AUTOSAR XML (schema 314)
package /ComponentType
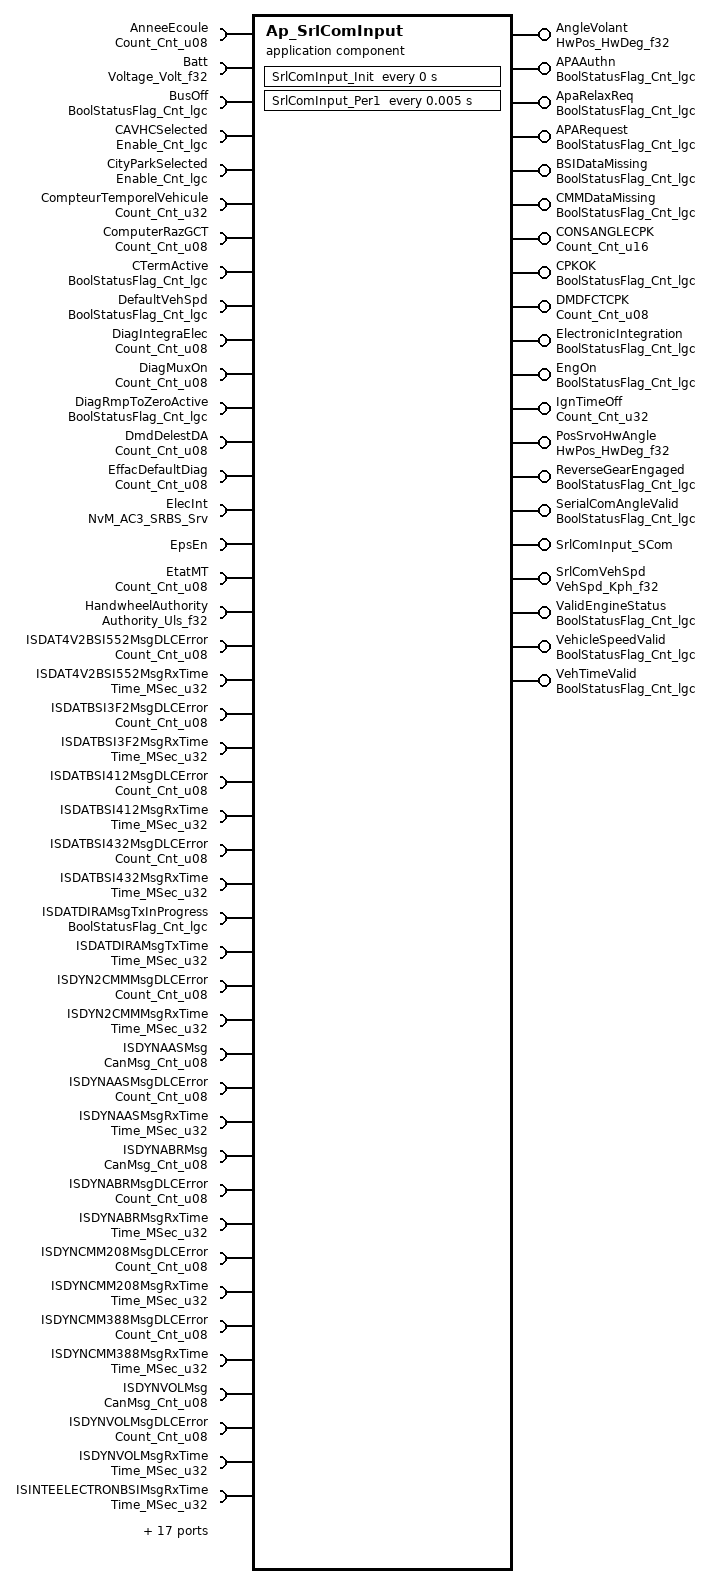
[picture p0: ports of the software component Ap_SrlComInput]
  application software component type Ap_SrlComInput
    20 x provide port:
      AngleVolant: unqueued-sender-com-spec{data-element=HwDeg_f32, can-invalidate=false, init-value=D_ZERO_ULS_F32}, provided-interface=HwPos_HwDeg_f32
      APAAuthn: unqueued-sender-com-spec{data-element=Cnt_lgc, can-invalidate=false, init-value=D_FALSE_CNT_LGC}, provided-interface=BoolStatusFlag_Cnt_lgc
      ApaRelaxReq: unqueued-sender-com-spec{data-element=Cnt_lgc, can-invalidate=false, init-value=D_FALSE_CNT_LGC}, provided-interface=BoolStatusFlag_Cnt_lgc
      APARequest: unqueued-sender-com-spec{data-element=Cnt_lgc, can-invalidate=false, init-value=D_FALSE_CNT_LGC}, provided-interface=BoolStatusFlag_Cnt_lgc
      BSIDataMissing: unqueued-sender-com-spec{data-element=Cnt_lgc, can-invalidate=false, init-value=D_TRUE_CNT_LGC}, provided-interface=BoolStatusFlag_Cnt_lgc
      CMMDataMissing: unqueued-sender-com-spec{data-element=Cnt_lgc, can-invalidate=false, init-value=D_TRUE_CNT_LGC}, provided-interface=BoolStatusFlag_Cnt_lgc
      CONSANGLECPK: unqueued-sender-com-spec{data-element=Cnt_u16, can-invalidate=false, init-value=D_ZERO_CNT_U16}, provided-interface=Count_Cnt_u16
      CPKOK: unqueued-sender-com-spec{data-element=Cnt_lgc, can-invalidate=false, init-value=D_FALSE_CNT_LGC}, provided-interface=BoolStatusFlag_Cnt_lgc
      DMDFCTCPK: unqueued-sender-com-spec{data-element=Cnt_u08, can-invalidate=false, init-value=D_ZERO_CNT_U8}, provided-interface=Count_Cnt_u08
      ElectronicIntegration: unqueued-sender-com-spec{data-element=Cnt_lgc, can-invalidate=false, init-value=D_FALSE_CNT_LGC}, provided-interface=BoolStatusFlag_Cnt_lgc
      EngOn: unqueued-sender-com-spec{data-element=Cnt_lgc, can-invalidate=false, init-value=D_FALSE_CNT_LGC}, provided-interface=BoolStatusFlag_Cnt_lgc
      IgnTimeOff: unqueued-sender-com-spec{data-element=Cnt_u32, can-invalidate=false, init-value=D_ZERO_CNT_U32}, provided-interface=Count_Cnt_u32
      PosSrvoHwAngle: unqueued-sender-com-spec{data-element=HwDeg_f32, can-invalidate=false, init-value=D_ZERO_ULS_F32}, provided-interface=HwPos_HwDeg_f32
      ReverseGearEngaged: unqueued-sender-com-spec{data-element=Cnt_lgc, can-invalidate=false, init-value=D_FALSE_CNT_LGC}, provided-interface=BoolStatusFlag_Cnt_lgc
      SerialComAngleValid: unqueued-sender-com-spec{data-element=Cnt_lgc, can-invalidate=false, init-value=D_FALSE_CNT_LGC}, provided-interface=BoolStatusFlag_Cnt_lgc
      SrlComInput_SCom: provided-interface=SrlComInput_SCom
        provided-com-specs:
          operation=GetNetworkDiagFltAcc, queue-length=1
          operation=ManualVehSpd, queue-length=1
          operation=ResetTimers, queue-length=1
          operation=VehSpdControl, queue-length=1
      SrlComVehSpd: unqueued-sender-com-spec{data-element=Kph_f32, can-invalidate=false, init-value=D_ZERO_ULS_F32}, provided-interface=VehSpd_Kph_f32
      ValidEngineStatus: unqueued-sender-com-spec{data-element=Cnt_lgc, can-invalidate=false, init-value=D_FALSE_CNT_LGC}, provided-interface=BoolStatusFlag_Cnt_lgc
      VehicleSpeedValid: unqueued-sender-com-spec{data-element=Cnt_lgc, can-invalidate=false, init-value=D_FALSE_CNT_LGC}, provided-interface=BoolStatusFlag_Cnt_lgc
      VehTimeValid: unqueued-sender-com-spec{data-element=Cnt_lgc, can-invalidate=false, init-value=D_FALSE_CNT_LGC}, provided-interface=BoolStatusFlag_Cnt_lgc
    61 x require port:
      AnneeEcoule: unqueued-receiver-com-spec{data-element=Cnt_u08, init-value=D_ZERO_CNT_U8}, required-interface=Count_Cnt_u08
      Batt: unqueued-receiver-com-spec{data-element=Volt_f32, init-value=D_ZERO_ULS_F32}, required-interface=Voltage_Volt_f32
      BusOff: unqueued-receiver-com-spec{data-element=Cnt_lgc, init-value=D_FALSE_CNT_LGC}, required-interface=BoolStatusFlag_Cnt_lgc
      CAVHCSelected: unqueued-receiver-com-spec{data-element=Cnt_lgc, init-value=D_FALSE_CNT_LGC}, required-interface=Enable_Cnt_lgc
      CityParkSelected: unqueued-receiver-com-spec{data-element=Cnt_lgc, init-value=D_FALSE_CNT_LGC}, required-interface=Enable_Cnt_lgc
      CompteurTemporelVehicule: unqueued-receiver-com-spec{data-element=Cnt_u32, init-value=D_ZERO_CNT_U32}, required-interface=Count_Cnt_u32
      ComputerRazGCT: unqueued-receiver-com-spec{data-element=Cnt_u08, init-value=D_ZERO_CNT_U8}, required-interface=Count_Cnt_u08
      CTermActive: unqueued-receiver-com-spec{data-element=Cnt_lgc, init-value=D_FALSE_CNT_LGC}, required-interface=BoolStatusFlag_Cnt_lgc
      DefaultVehSpd: unqueued-receiver-com-spec{data-element=Cnt_lgc, init-value=D_FALSE_CNT_LGC}, required-interface=BoolStatusFlag_Cnt_lgc
      DiagIntegraElec: unqueued-receiver-com-spec{data-element=Cnt_u08, init-value=D_ZERO_CNT_U8}, required-interface=Count_Cnt_u08
      DiagMuxOn: unqueued-receiver-com-spec{data-element=Cnt_u08, init-value=D_ZERO_CNT_U8}, required-interface=Count_Cnt_u08
      DiagRmpToZeroActive: unqueued-receiver-com-spec{data-element=Cnt_lgc, init-value=D_FALSE_CNT_LGC}, required-interface=BoolStatusFlag_Cnt_lgc
      DmdDelestDA: unqueued-receiver-com-spec{data-element=Cnt_u08, init-value=D_ZERO_CNT_U8}, required-interface=Count_Cnt_u08
      EffacDefaultDiag: unqueued-receiver-com-spec{data-element=Cnt_u08, init-value=D_ZERO_CNT_U8}, required-interface=Count_Cnt_u08
      ElecInt: required-com-specs=[EraseBlock, GetErrorStatus, InvalidateNvBlock, ReadBlock, SetRamBlockStatus, WriteBlock], required-interface=NvM_AC3_SRBS_Srv
      EpsEn: client-com-spec=OP_GET, required-interface=EpsEn
      EtatMT: unqueued-receiver-com-spec{data-element=Cnt_u08, init-value=D_ZERO_CNT_U8}, required-interface=Count_Cnt_u08
      HandwheelAuthority: unqueued-receiver-com-spec{data-element=Uls_f32, init-value=D_ZERO_ULS_F32}, required-interface=Authority_Uls_f32
      ISDAT4V2BSI552MsgDLCError: unqueued-receiver-com-spec{data-element=Cnt_u08, init-value=D_ZERO_CNT_U8}, required-interface=Count_Cnt_u08
      ISDAT4V2BSI552MsgRxTime: unqueued-receiver-com-spec{data-element=MSec_u32, init-value=D_ZERO_CNT_U32}, required-interface=Time_MSec_u32
      ISDATBSI3F2MsgDLCError: unqueued-receiver-com-spec{data-element=Cnt_u08, init-value=D_ZERO_CNT_U8}, required-interface=Count_Cnt_u08
      ISDATBSI3F2MsgRxTime: unqueued-receiver-com-spec{data-element=MSec_u32, init-value=D_ZERO_CNT_U32}, required-interface=Time_MSec_u32
      ISDATBSI412MsgDLCError: unqueued-receiver-com-spec{data-element=Cnt_u08, init-value=D_ZERO_CNT_U8}, required-interface=Count_Cnt_u08
      ISDATBSI412MsgRxTime: unqueued-receiver-com-spec{data-element=MSec_u32, init-value=D_ZERO_CNT_U32}, required-interface=Time_MSec_u32
      ISDATBSI432MsgDLCError: unqueued-receiver-com-spec{data-element=Cnt_u08, init-value=D_ZERO_CNT_U8}, required-interface=Count_Cnt_u08
      ISDATBSI432MsgRxTime: unqueued-receiver-com-spec{data-element=MSec_u32, init-value=D_ZERO_CNT_U32}, required-interface=Time_MSec_u32
      ISDATDIRAMsgTxInProgress: unqueued-receiver-com-spec{data-element=Cnt_lgc, init-value=D_FALSE_CNT_LGC}, required-interface=BoolStatusFlag_Cnt_lgc
      ISDATDIRAMsgTxTime: unqueued-receiver-com-spec{data-element=MSec_u32, init-value=D_ZERO_CNT_U32}, required-interface=Time_MSec_u32
      ISDYN2CMMMsgDLCError: unqueued-receiver-com-spec{data-element=Cnt_u08, init-value=D_ZERO_CNT_U8}, required-interface=Count_Cnt_u08
      ISDYN2CMMMsgRxTime: unqueued-receiver-com-spec{data-element=MSec_u32, init-value=D_ZERO_CNT_U32}, required-interface=Time_MSec_u32
      ISDYNAASMsg: unqueued-receiver-com-spec{data-element=Cnt_u08, init-value=T_CANMSGINIT_CNT_U08}, required-interface=CanMsg_Cnt_u08
      ISDYNAASMsgDLCError: unqueued-receiver-com-spec{data-element=Cnt_u08, init-value=D_ZERO_CNT_U8}, required-interface=Count_Cnt_u08
      ISDYNAASMsgRxTime: unqueued-receiver-com-spec{data-element=MSec_u32, init-value=D_ZERO_CNT_U32}, required-interface=Time_MSec_u32
      ISDYNABRMsg: unqueued-receiver-com-spec{data-element=Cnt_u08, init-value=T_CANMSGINIT_CNT_U08}, required-interface=CanMsg_Cnt_u08
      ISDYNABRMsgDLCError: unqueued-receiver-com-spec{data-element=Cnt_u08, init-value=D_ZERO_CNT_U8}, required-interface=Count_Cnt_u08
      ISDYNABRMsgRxTime: unqueued-receiver-com-spec{data-element=MSec_u32, init-value=D_ZERO_CNT_U32}, required-interface=Time_MSec_u32
      ISDYNCMM208MsgDLCError: unqueued-receiver-com-spec{data-element=Cnt_u08, init-value=D_ZERO_CNT_U8}, required-interface=Count_Cnt_u08
      ISDYNCMM208MsgRxTime: unqueued-receiver-com-spec{data-element=MSec_u32, init-value=D_ZERO_CNT_U32}, required-interface=Time_MSec_u32
      ISDYNCMM388MsgDLCError: unqueued-receiver-com-spec{data-element=Cnt_u08, init-value=D_ZERO_CNT_U8}, required-interface=Count_Cnt_u08
      ISDYNCMM388MsgRxTime: unqueued-receiver-com-spec{data-element=MSec_u32, init-value=D_ZERO_CNT_U32}, required-interface=Time_MSec_u32
      ISDYNVOLMsg: unqueued-receiver-com-spec{data-element=Cnt_u08, init-value=T_CANMSGINIT_CNT_U08}, required-interface=CanMsg_Cnt_u08
      ISDYNVOLMsgDLCError: unqueued-receiver-com-spec{data-element=Cnt_u08, init-value=D_ZERO_CNT_U8}, required-interface=Count_Cnt_u08
      ISDYNVOLMsgRxTime: unqueued-receiver-com-spec{data-element=MSec_u32, init-value=D_ZERO_CNT_U32}, required-interface=Time_MSec_u32
      ISINTEELECTRONBSIMsgRxTime: unqueued-receiver-com-spec{data-element=MSec_u32, init-value=D_ZERO_CNT_U32}, required-interface=Time_MSec_u32
      JourEcoule: unqueued-receiver-com-spec{data-element=Cnt_u16, init-value=D_ZERO_CNT_U16}, required-interface=Count_Cnt_u16
      LXASelected: unqueued-receiver-com-spec{data-element=Cnt_lgc, init-value=D_FALSE_CNT_LGC}, required-interface=Enable_Cnt_lgc
      MarcheARBVM: unqueued-receiver-com-spec{data-element=Cnt_u08, init-value=D_ZERO_CNT_U8}, required-interface=Count_Cnt_u08
      ModeDiag: unqueued-receiver-com-spec{data-element=Cnt_u08, init-value=D_ZERO_CNT_U8}, required-interface=Count_Cnt_u08
      NxtrDiagMgr: required-com-specs=[GetNTCActive, GetNTCFailed, GetNTCStatus, SetNTCStatus], required-interface=NxtrDiagMgr
      OutputRampMult: unqueued-receiver-com-spec{data-element=Uls_f32, init-value=D_ZERO_ULS_F32}, required-interface=UnityScalar
      RxMsgsSrlComSvcDft: unqueued-receiver-com-spec{data-element=Cnt_lgc, init-value=D_FALSE_CNT_LGC}, required-interface=Enable_Cnt_lgc
      SecondeEcoulee: unqueued-receiver-com-spec{data-element=Cnt_u32, init-value=D_ZERO_CNT_U32}, required-interface=Count_Cnt_u32
      ShutdownTime: required-com-specs=[EraseBlock, GetErrorStatus, InvalidateNvBlock, ReadBlock, SetRamBlockStatus, WriteBlock], required-interface=NvM_AC3_SRBS_Srv
      SrlComDriver_SCom: required-com-specs=[ElecIntStart, ElecIntStop, GetBusOffCounter], required-interface=SrlComDriver_SCom
      SrlComHwTrqValid: unqueued-receiver-com-spec{data-element=Cnt_lgc, init-value=D_FALSE_CNT_LGC}, required-interface=BoolStatusFlag_Cnt_lgc
      STTdSelected: unqueued-receiver-com-spec{data-element=Cnt_lgc, init-value=D_FALSE_CNT_LGC}, required-interface=Enable_Cnt_lgc
      SystemState: required-interface=SystemState
      SystemTime: required-interface=SystemTime
        required-com-specs:
          DtrmnElapsedTime_mS_u16
          DtrmnElapsedTime_mS_u32
          DtrmnElapsedTime_uS_u16
          DtrmnElapsedTime_uS_u32
          GetSystemTime_mS_u32
          GetSystemTime_uS_u32
      VehicleSpeed: unqueued-receiver-com-spec{data-element=Kph_f32, init-value=D_ZERO_ULS_F32}, required-interface=VehSpd_Kph_f32
      VHHTYPE: required-com-specs=[EraseBlock, GetErrorStatus, InvalidateNvBlock, ReadBlock, SetRamBlockStatus, WriteBlock], required-interface=NvM_AC3_SRBS_Srv
      VitesseVehicleBV: unqueued-receiver-com-spec{data-element=Cnt_u16, init-value=D_ZERO_CNT_U16}, required-interface=Count_Cnt_u16
  internal behavior Ap_SrlComInput_InternalBehavior: component=Ap_SrlComInput
    timing event SrlComInput_InitEvent: start-on-event=SrlComInput_Init, period=0
    timing event TMT_SrlComInput_Per1: start-on-event=SrlComInput_Per1, period=0.005
    4 x operation invoked event:
      OIT_SrlComInput_SCom_GetNetworkDiagFltAcc_SrlComInput_SCom_GetNetworkDiagFltAcc: start-on-event=SrlComInput_SCom_GetNetworkDiagFltAcc, operation=SrlComInput_SCom.GetNetworkDiagFltAcc
      OIT_SrlComInput_SCom_ManualVehSpd_SrlComInput_SCom_ManualVehSpd: start-on-event=SrlComInput_SCom_ManualVehSpd, operation=SrlComInput_SCom.ManualVehSpd
      OIT_SrlComInput_SCom_ResetTimers_SrlComInput_SCom_ResetTimers: start-on-event=SrlComInput_SCom_ResetTimers, operation=SrlComInput_SCom.ResetTimers
      OIT_SrlComInput_SCom_VehSpdControl_SrlComInput_SCom_VehSpdControl: start-on-event=SrlComInput_SCom_VehSpdControl, operation=SrlComInput_SCom.VehSpdControl
    mode switch event MST_SrlComInput_Trns1_0: start-on-event=SrlComInput_Trns1, activation=ENTRY, mode=SystemState.Mode.OFF
    per instance memory ElecIntData: type=Boolean, type-definition=/DataType/Boolean
    per instance memory ShutdownTimeData: type=ShutdownTimeType, type-definition=/DataType/ShutdownTimeType
    per instance memory VVHTYPEData: type=UInt8, type-definition=/DataType/UInt8
    port-api-options:
      enable-take-address=false, indirect-api=false, port=AngleVolant
      enable-take-address=false, indirect-api=false, port=AnneeEcoule
      enable-take-address=false, indirect-api=false, port=APAAuthn
      enable-take-address=false, indirect-api=false, port=ApaRelaxReq
      enable-take-address=false, indirect-api=false, port=APARequest
      enable-take-address=false, indirect-api=false, port=Batt
      enable-take-address=false, indirect-api=false, port=BSIDataMissing
      enable-take-address=false, indirect-api=false, port=BusOff
      enable-take-address=false, indirect-api=false, port=CAVHCSelected
      enable-take-address=false, indirect-api=false, port=CityParkSelected
      enable-take-address=false, indirect-api=false, port=CMMDataMissing
      enable-take-address=false, indirect-api=false, port=CompteurTemporelVehicule
      enable-take-address=false, indirect-api=false, port=ComputerRazGCT
      enable-take-address=false, indirect-api=false, port=CONSANGLECPK
      enable-take-address=false, indirect-api=false, port=CPKOK
      enable-take-address=false, indirect-api=false, port=CTermActive
      enable-take-address=false, indirect-api=false, port=DefaultVehSpd
      enable-take-address=false, indirect-api=false, port=DiagIntegraElec
      enable-take-address=false, indirect-api=false, port=DiagMuxOn
      enable-take-address=false, indirect-api=false, port=DiagRmpToZeroActive
      enable-take-address=false, indirect-api=false, port=DmdDelestDA
      enable-take-address=false, indirect-api=false, port=DMDFCTCPK
      enable-take-address=false, indirect-api=false, port=EffacDefaultDiag
      enable-take-address=false, indirect-api=false, port=ElecInt
      enable-take-address=false, indirect-api=false, port=ElectronicIntegration
      enable-take-address=false, indirect-api=false, port=EngOn
      enable-take-address=false, indirect-api=false, port=EpsEn
      enable-take-address=false, indirect-api=false, port=EtatMT
      enable-take-address=false, indirect-api=false, port=HandwheelAuthority
      enable-take-address=false, indirect-api=false, port=IgnTimeOff
      enable-take-address=false, indirect-api=false, port=ISDAT4V2BSI552MsgDLCError
      enable-take-address=false, indirect-api=false, port=ISDAT4V2BSI552MsgRxTime
      enable-take-address=false, indirect-api=false, port=ISDATBSI3F2MsgDLCError
      enable-take-address=false, indirect-api=false, port=ISDATBSI3F2MsgRxTime
      enable-take-address=false, indirect-api=false, port=ISDATBSI412MsgDLCError
      enable-take-address=false, indirect-api=false, port=ISDATBSI412MsgRxTime
      enable-take-address=false, indirect-api=false, port=ISDATBSI432MsgDLCError
      enable-take-address=false, indirect-api=false, port=ISDATBSI432MsgRxTime
      enable-take-address=false, indirect-api=false, port=ISDATDIRAMsgTxInProgress
      enable-take-address=false, indirect-api=false, port=ISDATDIRAMsgTxTime
      enable-take-address=false, indirect-api=false, port=ISDYN2CMMMsgDLCError
      enable-take-address=false, indirect-api=false, port=ISDYN2CMMMsgRxTime
      enable-take-address=false, indirect-api=false, port=ISDYNAASMsg
      enable-take-address=false, indirect-api=false, port=ISDYNAASMsgDLCError
      enable-take-address=false, indirect-api=false, port=ISDYNAASMsgRxTime
      enable-take-address=false, indirect-api=false, port=ISDYNABRMsg
      enable-take-address=false, indirect-api=false, port=ISDYNABRMsgDLCError
      enable-take-address=false, indirect-api=false, port=ISDYNABRMsgRxTime
      enable-take-address=false, indirect-api=false, port=ISDYNCMM208MsgDLCError
      enable-take-address=false, indirect-api=false, port=ISDYNCMM208MsgRxTime
      enable-take-address=false, indirect-api=false, port=ISDYNCMM388MsgDLCError
      enable-take-address=false, indirect-api=false, port=ISDYNCMM388MsgRxTime
      enable-take-address=false, indirect-api=false, port=ISDYNVOLMsg
      enable-take-address=false, indirect-api=false, port=ISDYNVOLMsgDLCError
      enable-take-address=false, indirect-api=false, port=ISDYNVOLMsgRxTime
      enable-take-address=false, indirect-api=false, port=ISINTEELECTRONBSIMsgRxTime
      enable-take-address=false, indirect-api=false, port=JourEcoule
      enable-take-address=false, indirect-api=false, port=LXASelected
      enable-take-address=false, indirect-api=false, port=MarcheARBVM
      enable-take-address=false, indirect-api=false, port=ModeDiag
      enable-take-address=false, indirect-api=false, port=NxtrDiagMgr
      enable-take-address=false, indirect-api=false, port=OutputRampMult
      enable-take-address=false, indirect-api=false, port=PosSrvoHwAngle
      enable-take-address=false, indirect-api=false, port=ReverseGearEngaged
      enable-take-address=false, indirect-api=false, port=RxMsgsSrlComSvcDft
      enable-take-address=false, indirect-api=false, port=SecondeEcoulee
      enable-take-address=false, indirect-api=false, port=SerialComAngleValid
      enable-take-address=false, indirect-api=false, port=ShutdownTime
      enable-take-address=false, indirect-api=false, port=SrlComDriver_SCom
      enable-take-address=false, indirect-api=false, port=SrlComHwTrqValid
      enable-take-address=false, indirect-api=false, port=SrlComInput_SCom
      enable-take-address=false, indirect-api=false, port=SrlComVehSpd
      enable-take-address=false, indirect-api=false, port=STTdSelected
      enable-take-address=false, indirect-api=false, port=SystemState
      enable-take-address=false, indirect-api=false, port=SystemTime
      enable-take-address=false, indirect-api=false, port=ValidEngineStatus
      enable-take-address=false, indirect-api=false, port=VehicleSpeed
      enable-take-address=false, indirect-api=false, port=VehicleSpeedValid
      enable-take-address=false, indirect-api=false, port=VehTimeValid
      enable-take-address=false, indirect-api=false, port=VHHTYPE
      enable-take-address=false, indirect-api=false, port=VitesseVehicleBV
    7 x runnable:
      SrlComInput_Init
        data read access READ_LXASelected_Cnt_lgc: data-element=LXASelected.Cnt_lgc
        data read access READ_STTdSelected_Cnt_lgc: data-element=STTdSelected.Cnt_lgc
        data write access WRITE_ElectronicIntegration_Cnt_lgc: data-element=ElectronicIntegration.Cnt_lgc
        sync call SC_NxtrDiagMgr_GetNTCFailed: operation=NxtrDiagMgr.GetNTCFailed, timeout=0
        sync call SC_SystemTime_GetSystemTime_mS_u32: operation=SystemTime.GetSystemTime_mS_u32, timeout=0
      SrlComInput_Per1
        53 x data read access:
          READ_AnneeEcoule_Cnt_u08: data-element=AnneeEcoule.Cnt_u08
          READ_Batt_Volt_f32: data-element=Batt.Volt_f32
          READ_BusOff_Cnt_lgc: data-element=BusOff.Cnt_lgc
          READ_CAVHCSelected_Cnt_lgc: data-element=CAVHCSelected.Cnt_lgc
          READ_CityParkSelected_Cnt_lgc: data-element=CityParkSelected.Cnt_lgc
          READ_CompteurTemporelVehicule_Cnt_u32: data-element=CompteurTemporelVehicule.Cnt_u32
          READ_ComputerRazGCT_Cnt_u08: data-element=ComputerRazGCT.Cnt_u08
          READ_CTermActive_Cnt_lgc: data-element=CTermActive.Cnt_lgc
          READ_DefaultVehSpd_Cnt_lgc: data-element=DefaultVehSpd.Cnt_lgc
          READ_DiagIntegraElec_Cnt_u08: data-element=DiagIntegraElec.Cnt_u08
          READ_DiagMuxOn_Cnt_u08: data-element=DiagMuxOn.Cnt_u08
          READ_DiagRmpToZeroActive_Cnt_lgc: data-element=DiagRmpToZeroActive.Cnt_lgc
          READ_DmdDelestDA_Cnt_u08: data-element=DmdDelestDA.Cnt_u08
          READ_EffacDefaultDiag_Cnt_u08: data-element=EffacDefaultDiag.Cnt_u08
          READ_EtatMT_Cnt_u08: data-element=EtatMT.Cnt_u08
          READ_HandwheelAuthority_Uls_f32: data-element=HandwheelAuthority.Uls_f32
          READ_ISDAT4V2BSI552MsgDLCError_Cnt_u08: data-element=ISDAT4V2BSI552MsgDLCError.Cnt_u08
          READ_ISDAT4V2BSI552MsgRxTime_MSec_u32: data-element=ISDAT4V2BSI552MsgRxTime.MSec_u32
          READ_ISDATBSI3F2MsgDLCError_Cnt_u08: data-element=ISDATBSI3F2MsgDLCError.Cnt_u08
          READ_ISDATBSI3F2MsgRxTime_MSec_u32: data-element=ISDATBSI3F2MsgRxTime.MSec_u32
          READ_ISDATBSI412MsgDLCError_Cnt_u08: data-element=ISDATBSI412MsgDLCError.Cnt_u08
          READ_ISDATBSI412MsgRxTime_MSec_u32: data-element=ISDATBSI412MsgRxTime.MSec_u32
          READ_ISDATBSI432MsgDLCError_Cnt_u08: data-element=ISDATBSI432MsgDLCError.Cnt_u08
          READ_ISDATBSI432MsgRxTime_MSec_u32: data-element=ISDATBSI432MsgRxTime.MSec_u32
          READ_ISDATDIRAMsgTxInProgress_Cnt_lgc: data-element=ISDATDIRAMsgTxInProgress.Cnt_lgc
          READ_ISDATDIRAMsgTxTime_MSec_u32: data-element=ISDATDIRAMsgTxTime.MSec_u32
          READ_ISDYN2CMMMsgDLCError_Cnt_u08: data-element=ISDYN2CMMMsgDLCError.Cnt_u08
          READ_ISDYN2CMMMsgRxTime_MSec_u32: data-element=ISDYN2CMMMsgRxTime.MSec_u32
          READ_ISDYNAASMsg_Cnt_u08: data-element=ISDYNAASMsg.Cnt_u08
          READ_ISDYNAASMsgDLCError_Cnt_u08: data-element=ISDYNAASMsgDLCError.Cnt_u08
          READ_ISDYNAASMsgRxTime_MSec_u32: data-element=ISDYNAASMsgRxTime.MSec_u32
          READ_ISDYNABRMsg_Cnt_u08: data-element=ISDYNABRMsg.Cnt_u08
          READ_ISDYNABRMsgDLCError_Cnt_u08: data-element=ISDYNABRMsgDLCError.Cnt_u08
          READ_ISDYNABRMsgRxTime_MSec_u32: data-element=ISDYNABRMsgRxTime.MSec_u32
          READ_ISDYNCMM208MsgDLCError_Cnt_u08: data-element=ISDYNCMM208MsgDLCError.Cnt_u08
          READ_ISDYNCMM208MsgRxTime_MSec_u32: data-element=ISDYNCMM208MsgRxTime.MSec_u32
          READ_ISDYNCMM388MsgDLCError_Cnt_u08: data-element=ISDYNCMM388MsgDLCError.Cnt_u08
          READ_ISDYNCMM388MsgRxTime_MSec_u32: data-element=ISDYNCMM388MsgRxTime.MSec_u32
          READ_ISDYNVOLMsg_Cnt_u08: data-element=ISDYNVOLMsg.Cnt_u08
          READ_ISDYNVOLMsgDLCError_Cnt_u08: data-element=ISDYNVOLMsgDLCError.Cnt_u08
          READ_ISDYNVOLMsgRxTime_MSec_u32: data-element=ISDYNVOLMsgRxTime.MSec_u32
          READ_ISINTEELECTRONBSIMsgRxTime_MSec_u32: data-element=ISINTEELECTRONBSIMsgRxTime.MSec_u32
          READ_JourEcoule_Cnt_u16: data-element=JourEcoule.Cnt_u16
          READ_LXASelected_Cnt_lgc: data-element=LXASelected.Cnt_lgc
          READ_MarcheARBVM_Cnt_u08: data-element=MarcheARBVM.Cnt_u08
          READ_ModeDiag_Cnt_u08: data-element=ModeDiag.Cnt_u08
          READ_OutputRampMult_Uls_f32: data-element=OutputRampMult.Uls_f32
          READ_RxMsgsSrlComSvcDft_Cnt_lgc: data-element=RxMsgsSrlComSvcDft.Cnt_lgc
          READ_SecondeEcoulee_Cnt_u32: data-element=SecondeEcoulee.Cnt_u32
          READ_SrlComHwTrqValid_Cnt_lgc: data-element=SrlComHwTrqValid.Cnt_lgc
          READ_STTdSelected_Cnt_lgc: data-element=STTdSelected.Cnt_lgc
          READ_VehicleSpeed_Kph_f32: data-element=VehicleSpeed.Kph_f32
          READ_VitesseVehicleBV_Cnt_u16: data-element=VitesseVehicleBV.Cnt_u16
        19 x data write access:
          WRITE_AngleVolant_HwDeg_f32: data-element=AngleVolant.HwDeg_f32
          WRITE_APAAuthn_Cnt_lgc: data-element=APAAuthn.Cnt_lgc
          WRITE_ApaRelaxReq_Cnt_lgc: data-element=ApaRelaxReq.Cnt_lgc
          WRITE_APARequest_Cnt_lgc: data-element=APARequest.Cnt_lgc
          WRITE_BSIDataMissing_Cnt_lgc: data-element=BSIDataMissing.Cnt_lgc
          WRITE_CMMDataMissing_Cnt_lgc: data-element=CMMDataMissing.Cnt_lgc
          WRITE_CONSANGLECPK_Cnt_u16: data-element=CONSANGLECPK.Cnt_u16
          WRITE_CPKOK_Cnt_lgc: data-element=CPKOK.Cnt_lgc
          WRITE_DMDFCTCPK_Cnt_u08: data-element=DMDFCTCPK.Cnt_u08
          WRITE_ElectronicIntegration_Cnt_lgc: data-element=ElectronicIntegration.Cnt_lgc
          WRITE_EngOn_Cnt_lgc: data-element=EngOn.Cnt_lgc
          WRITE_IgnTimeOff_Cnt_u32: data-element=IgnTimeOff.Cnt_u32
          WRITE_PosSrvoHwAngle_HwDeg_f32: data-element=PosSrvoHwAngle.HwDeg_f32
          WRITE_ReverseGearEngaged_Cnt_lgc: data-element=ReverseGearEngaged.Cnt_lgc
          WRITE_SerialComAngleValid_Cnt_lgc: data-element=SerialComAngleValid.Cnt_lgc
          WRITE_SrlComVehSpd_Kph_f32: data-element=SrlComVehSpd.Kph_f32
          WRITE_ValidEngineStatus_Cnt_lgc: data-element=ValidEngineStatus.Cnt_lgc
          WRITE_VehicleSpeedValid_Cnt_lgc: data-element=VehicleSpeedValid.Cnt_lgc
          WRITE_VehTimeValid_Cnt_lgc: data-element=VehTimeValid.Cnt_lgc
        9 x sync call, all with timeout=0:
          SC_ElecInt_WriteBlock: operation=ElecInt.WriteBlock
          SC_EpsEn_OP_GET: operation=EpsEn.OP_GET
          SC_NxtrDiagMgr_GetNTCFailed: operation=NxtrDiagMgr.GetNTCFailed
          SC_NxtrDiagMgr_SetNTCStatus: operation=NxtrDiagMgr.SetNTCStatus
          SC_SrlComDriver_SCom_ElecIntStart: operation=SrlComDriver_SCom.ElecIntStart
          SC_SrlComDriver_SCom_ElecIntStop: operation=SrlComDriver_SCom.ElecIntStop
          SC_SystemTime_DtrmnElapsedTime_mS_u16: operation=SystemTime.DtrmnElapsedTime_mS_u16
          SC_SystemTime_GetSystemTime_mS_u32: operation=SystemTime.GetSystemTime_mS_u32
          SC_VHHTYPE_WriteBlock: operation=VHHTYPE.WriteBlock
      SrlComInput_SCom_GetNetworkDiagFltAcc
      SrlComInput_SCom_ManualVehSpd
      SrlComInput_SCom_ResetTimers
      SrlComInput_SCom_VehSpdControl
      SrlComInput_Trns1
        5 x data receive point:
          REC_AnneeEcoule_Cnt_u08: data-element=AnneeEcoule.Cnt_u08
          REC_CompteurTemporelVehicule_Cnt_u32: data-element=CompteurTemporelVehicule.Cnt_u32
          REC_ISDAT4V2BSI552MsgRxTime_MSec_u32: data-element=ISDAT4V2BSI552MsgRxTime.MSec_u32
          REC_JourEcoule_Cnt_u16: data-element=JourEcoule.Cnt_u16
          REC_SecondeEcoulee_Cnt_u32: data-element=SecondeEcoulee.Cnt_u32
        sync call SC_NxtrDiagMgr_GetNTCFailed: operation=NxtrDiagMgr.GetNTCFailed, timeout=0
        sync call SC_ShutdownTime_WriteBlock: operation=ShutdownTime.WriteBlock, timeout=0
    service-needss:
      swc nv block needs VVHTYPE: n-data-sets=0, readonly=false, reliability=LOW, resistant-to-changed-sw=false, restore-at-start=false, write-only-once=false, writing-frequency=0, writing-priority=LOW, mirror-block=VVHTYPEData
      swc nv block needs ShutdownTime: n-data-sets=0, readonly=false, reliability=LOW, resistant-to-changed-sw=false, restore-at-start=false, write-only-once=false, writing-frequency=0, writing-priority=LOW, mirror-block=ShutdownTimeData
      swc nv block needs ElecInt: n-data-sets=0, readonly=false, reliability=LOW, resistant-to-changed-sw=false, restore-at-start=false, write-only-once=false, writing-frequency=0, writing-priority=LOW, mirror-block=ElecIntData
  swc implementation Ap_SrlComInput_Implementation: behavior=Ap_SrlComInput_InternalBehavior
    code-descriptors:
      code Code: type=SRC
